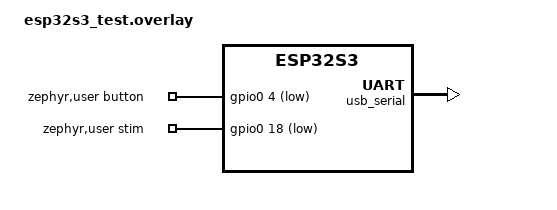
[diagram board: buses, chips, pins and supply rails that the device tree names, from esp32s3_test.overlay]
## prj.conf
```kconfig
# --- Basico ---
CONFIG_GPIO=y
CONFIG_PRINTK=y
CONFIG_MAIN_STACK_SIZE=4096
CONFIG_SYS_CLOCK_TICKS_PER_SEC=1000
CONFIG_ESP32_USE_UNSUPPORTED_REVISION=y

# --- Instrumentacao: CPU e pilhas ---
CONFIG_THREAD_NAME=y
CONFIG_THREAD_STACK_INFO=y
CONFIG_INIT_STACKS=y
CONFIG_THREAD_RUNTIME_STATS=y
CONFIG_SCHED_THREAD_USAGE=y
CONFIG_SCHED_THREAD_USAGE_ALL=y
CONFIG_THREAD_ANALYZER=y
CONFIG_THREAD_ANALYZER_USE_PRINTK=y

# --- Mesma prioridade para a worker e a system workqueue (comparacao justa) ---
CONFIG_SYSTEM_WORKQUEUE_PRIORITY=1
CONFIG_ESPTOOLPY_FLASHSIZE_16MB=y

#--- Usando o LED ad placa para o LAB8 ---
```

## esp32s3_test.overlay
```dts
#include <zephyr/dt-bindings/gpio/gpio.h>
#include <espressif/esp32s3/esp32s3_wroom_n16.dtsi>

&uart0 {
    status = "disabled";
};

&usb_serial {
    status = "okay";
};

/ {
    chosen {
        zephyr,console = &usb_serial;
        zephyr,shell-uart = &usb_serial;
    };

    zephyr,user {
        button-gpios = <&gpio0 4 (GPIO_ACTIVE_LOW | GPIO_PULL_UP)>;
        stim-gpios = <&gpio0 18 GPIO_ACTIVE_LOW>;
    };
};
```

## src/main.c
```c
#include "bench.h"
#include <zephyr/debug/thread_analyzer.h>
#include <zephyr/kernel.h>

#define ZU DT_PATH(zephyr_user)

const struct gpio_dt_spec button = GPIO_DT_SPEC_GET(ZU, button_gpios);
const struct gpio_dt_spec stim = GPIO_DT_SPEC_GET(ZU, stim_gpios);

BUILD_ASSERT(CONFIG_APP_PULSE_WIDTH_MS < CONFIG_APP_EVENT_PERIOD_MS,
						 "APP_PULSE_WIDTH_MS deve ser menor que APP_EVENT_PERIOD_MS");

#ifdef CONFIG_APP_STIMULUS
/* Gera um pulso no pino de estimulo e espera o restante do periodo */
static void pulse(void) {
	t_stim = k_cycle_get_32(); /* <- ponto t_stim */
	atomic_inc(&ev_generated);
	gpio_pin_set_dt(&stim, 1);
	k_msleep(CONFIG_APP_PULSE_WIDTH_MS);
	gpio_pin_set_dt(&stim, 0);
	k_msleep(CONFIG_APP_EVENT_PERIOD_MS - CONFIG_APP_PULSE_WIDTH_MS);
}

static void print_report(const k_thread_runtime_stats_t *a,
												 const k_thread_runtime_stats_t *b, int64_t window_ms) {
	uint64_t total = b->execution_cycles - a->execution_cycles;
	uint64_t idle = 0U;

#ifdef CONFIG_SCHED_THREAD_USAGE_ALL
	idle = b->idle_cycles - a->idle_cycles;
#endif

	/* CPU ocupada em centesimos de % (0..10000) */
	uint32_t busy =
			(total > idle) ? (uint32_t)(((total - idle) * 10000ULL) / total) : 0U;

	/* CPU estimada so a partir do tempo em app_process_event() */
	uint64_t proc_ns = k_cyc_to_ns_floor64(lat_proc_dur.sum);
	uint32_t est = (uint32_t)(proc_ns / ((uint64_t)window_ms * 100ULL));
	uint32_t generated = (uint32_t)atomic_get(&ev_generated);
	uint32_t detected = (uint32_t)atomic_get(&ev_detected);
	uint32_t processed = (uint32_t)atomic_get(&ev_processed);

	printk("\n===== RELATORIO (%s) =====\n", mode_name());
	printk("janela               : %lld ms\n", window_ms);
	printk("eventos gerados      : %u\n", generated);
	printk("eventos detectados   : %u\n", detected);
	printk("eventos processados  : %u\n", processed);
	printk("eventos perdidos     : %u\n",
				 generated > processed ? generated - processed : 0U);

	lat_print("lat_detect", &lat_detect);
	lat_print("lat_handoff", &lat_handoff);
	lat_print("lat_process", &lat_process);
	lat_print("lat_proc_dur", &lat_proc_dur);

	printk("CPU ocupada (kernel) : %u.%02u %%\n", busy / 100U, busy % 100U);
	printk("CPU estimada (proc.) : %u.%02u %%\n", est / 100U, est % 100U);

#ifdef CONFIG_APP_HEARTBEAT
	uint64_t hb = k_cyc_to_ns_floor64(hb_max_dt);
	printk("heartbeat: maior intervalo = %u.%02u ms (baseline ~1-2 ms)\n",
				 (uint32_t)(hb / 1000000ULL), (uint32_t)((hb % 1000000ULL) / 10000ULL));
#endif

	printk("sizeof(k_thread)=%u  sizeof(k_sem)=%u  sizeof(k_work)=%u  "
				 "sizeof(k_work_q)=%u  (bytes)\n",
				 (unsigned int)sizeof(struct k_thread),
				 (unsigned int)sizeof(struct k_sem),
				 (unsigned int)sizeof(struct k_work),
				 (unsigned int)sizeof(struct k_work_q));

	printk("CSV,SUM,%s,poll_ms=%d,proc_us=%d,period_ms=%d,pulse_ms=%d,"
				 "gen=%u,det=%u,proc=%u,cpu_x100=%u,cpu_est_x100=%u\n",
				 mode_name(), CONFIG_APP_POLL_PERIOD_MS, CONFIG_APP_PROCESSING_US,
				 CONFIG_APP_EVENT_PERIOD_MS, CONFIG_APP_PULSE_WIDTH_MS, generated,
				 detected, processed, busy, est);

#ifdef CONFIG_THREAD_ANALYZER
	printk("\n----- Thread Analyzer -----\n");
	thread_analyzer_print(0); /* versoes antigas: thread_analyzer_print() */
#endif
}

static void run_benchmark(void) {
	k_thread_runtime_stats_t s0, s1;

	printk("Aquecimento: %d eventos...\n", CONFIG_APP_WARMUP_EVENTS);
	for (int i = 0; i < CONFIG_APP_WARMUP_EVENTS; i++) {
		pulse();
	}
	k_msleep(100 + CONFIG_APP_PROCESSING_US / 1000);

	bench_reset_all();

	k_thread_runtime_stats_all_get(&s0);

	int64_t t0 = k_uptime_get();

	measuring = true;

	printk("Medindo: %d eventos, periodo %d ms...\n", CONFIG_APP_NUM_EVENTS,
				 CONFIG_APP_EVENT_PERIOD_MS);

	for (int i = 0; i < CONFIG_APP_NUM_EVENTS; i++) {
		pulse();
	}

	k_msleep(100 + CONFIG_APP_PROCESSING_US / 1000); /* ultimo evento */

	measuring = false;

	k_thread_runtime_stats_all_get(&s1);

	int64_t window = k_uptime_get() - t0;

	print_report(&s0, &s1, window);
}
#endif /* CONFIG_APP_STIMULUS */

int main(void) {
	k_thread_priority_set(k_current_get(), CONFIG_APP_MAIN_PRIORITY);

	if (!gpio_is_ready_dt(&button) ||
 	    !gpio_is_ready_dt(&stim)) {
    	    printk("ERRO: dispositivo nao esta pronto\n");
    	    return 0;
	}

	if (gpio_pin_configure_dt(&stim, GPIO_OUTPUT_INACTIVE) < 0 ||
	    gpio_pin_configure_dt(&button, GPIO_INPUT) < 0) {
 	    printk("ERRO: falha ao configurar os GPIOs\n");
    	    return 0;
	}

	bench_reset_all();

	printk("\n*** Hands-on eventos | modo: %s ***\n", mode_name());

	printk("hw cycles/s = %u  | tick = %d Hz\n",
				 (uint32_t)sys_clock_hw_cycles_per_sec(),
				 CONFIG_SYS_CLOCK_TICKS_PER_SEC);

	heartbeat_start();

	if (mode_start() < 0) {
		printk("ERRO: falha ao iniciar o modo\n");
		return 0;
	}

#ifdef CONFIG_APP_STIMULUS
	run_benchmark();
#else

	/* Modo manual: use o botao fisico; status a cada 10 s */
	while (1) {
		k_msleep(10000);
		printk("[status] eventos processados = %ld\n",
					 (long)atomic_get(&ev_processed));

#ifdef CONFIG_THREAD_ANALYZER
		thread_analyzer_print(0);
#endif
	}

#endif
	return 0;
}
```

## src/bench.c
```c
#include "bench.h"

atomic_t ev_generated;
atomic_t ev_detected;
atomic_t ev_processed;
volatile bool measuring;
volatile uint32_t t_stim;
volatile uint32_t hb_max_dt;
struct lat_stat lat_detect, lat_handoff, lat_process, lat_proc_dur;

void lat_reset(struct lat_stat *s) {
	s->n = 0U;
	s->min = UINT32_MAX;
	s->max = 0U;
	s->sum = 0U;
}

void lat_add(struct lat_stat *s, uint32_t cycles) {
	s->n++;
	s->sum += cycles;
	if (cycles < s->min) {
		s->min = cycles;
	}

	if (cycles > s->max) {
		s->max = cycles;
	}
}

void bench_reset_all(void) {
	lat_reset(&lat_detect);
	lat_reset(&lat_handoff);
	lat_reset(&lat_process);
	lat_reset(&lat_proc_dur);

	atomic_set(&ev_generated, 0);
	atomic_set(&ev_detected, 0);

	atomic_set(&ev_processed, 0);

	hb_max_dt = 0U;
}

#define US_I(ns) ((uint32_t)((ns) / 1000ULL))

#define US_F(ns) ((uint32_t)(((ns) % 1000ULL) / 10ULL))

void lat_print(const char *name, const struct lat_stat *s) {
	if (s->n == 0U) {
		printk("%-13s: sem amostras\n", name);
		return;
	}

	uint64_t mn = k_cyc_to_ns_floor64(s->min);
	uint64_t av = k_cyc_to_ns_floor64(s->sum / s->n);
	uint64_t mx = k_cyc_to_ns_floor64(s->max);

	printk("%-13s: n=%-4u min=%u.%02u  med=%u.%02u  max=%u.%02u  (us)\n", name,
				 s->n, US_I(mn), US_F(mn), US_I(av), US_F(av), US_I(mx), US_F(mx));

	printk("CSV,LAT,%s,%s,%u,%u,%u,%u\n", mode_name(), name, s->n, (uint32_t)mn,
				 (uint32_t)av, (uint32_t)mx);
}
  

/* Tratamento do evento: identico nas quatro arquiteturas */
void app_process_event(void)
{
    uint32_t t0 = k_cycle_get_32();

    atomic_inc(&ev_processed);

    if (CONFIG_APP_PROCESSING_US > 0) {
        k_busy_wait(CONFIG_APP_PROCESSING_US);
    }

#ifdef CONFIG_APP_VERBOSE
    printk("evento processado #%ld\n",
           (long)atomic_get(&ev_processed));
#endif

    if (measuring) {
        lat_add(&lat_proc_dur, k_cycle_get_32() - t0);
    }
}

#ifdef CONFIG_APP_VERBOSE
	printk("evento processado #%ld\n", (long)atomic_get(&ev_processed));
#endif

#ifdef CONFIG_APP_HEARTBEAT

/* Thread periodica de alta prioridade: mede o quanto o escalonamento
 * e atrasado (ex.: por uma ISR longa). Baseline ~1-2 ms (1 tick). */
K_THREAD_STACK_DEFINE(hb_stack, 1024);

static struct k_thread hb_data;

static void hb_thread(void *p1, void *p2, void *p3) {
	uint32_t last = k_cycle_get_32();

	while (1) {
		k_msleep(1);
		uint32_t now = k_cycle_get_32();
		uint32_t dt = now - last;
		last = now;

		if (measuring && dt > hb_max_dt) {
			hb_max_dt = dt;
		}
	}
}

void heartbeat_start(void) {
	k_tid_t tid =
			k_thread_create(&hb_data, hb_stack, K_THREAD_STACK_SIZEOF(hb_stack),
											hb_thread, NULL, NULL, NULL, 0, 0, K_NO_WAIT);

	k_thread_name_set(tid, "heartbeat");
}

#else

void heartbeat_start(void) {}

#endif
```

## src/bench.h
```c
#ifndef BENCH_H_
#define BENCH_H_

#include <stdbool.h>
#include <stdint.h>

#include <zephyr/device.h>
#include <zephyr/drivers/gpio.h>
#include <zephyr/kernel.h>
#include <zephyr/sys/atomic.h>

/* LED RGB integrado e GPIOs do experimento */
extern const struct gpio_dt_spec button;
extern const struct gpio_dt_spec stim;

/* Contadores e estado da medicao */
extern atomic_t ev_generated;
extern atomic_t ev_detected;
extern atomic_t ev_processed;

extern volatile bool measuring;
extern volatile uint32_t t_stim;
extern volatile uint32_t hb_max_dt;

/* Estatisticas de latencia */
struct lat_stat {
    uint32_t n;
    uint32_t min;
    uint32_t max;
    uint64_t sum;
};

extern struct lat_stat lat_detect;
extern struct lat_stat lat_handoff;
extern struct lat_stat lat_process;
extern struct lat_stat lat_proc_dur;

/* Funcoes do benchmark */
void lat_reset(struct lat_stat *s);
void lat_add(struct lat_stat *s, uint32_t cycles);
void lat_print(const char *name, const struct lat_stat *s);
void bench_reset_all(void);

void app_process_event(void);

void heartbeat_start(void);
int mode_start(void);
const char *mode_name(void);

#endif /* BENCH_H_ */
```
